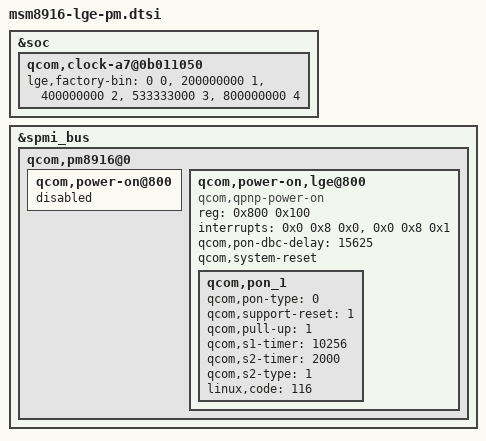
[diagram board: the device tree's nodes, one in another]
/* Copyright (c) 2012, Code Aurora Forum. All rights reserved.
 *
 * This program is free software; you can redistribute it and/or modify
 * it under the terms of the GNU General Public License version 2 and
 * only version 2 as published by the Free Software Foundation.
 *
 * This program is distributed in the hope that it will be useful,
 * but WITHOUT ANY WARRANTY; without even the implied warranty of
 * MERCHANTABILITY or FITNESS FOR A PARTICULAR PURPOSE.  See the
 * GNU General Public License for more details.
 */

&soc{
	qcom,clock-a7@0b011050	{
		lge,factory-bin =
			<          0 0>,
			<  200000000 1>,
			<  400000000 2>,
			<  533333000 3>,
			<  800000000 4>;
	};
};

&spmi_bus {
	qcom,pm8916@0 {
		qcom,power-on@800 {
			status = "disable";
		};
		qcom,power-on,lge@800 {
			compatible = "qcom,qpnp-power-on";
			reg = <0x800 0x100>;
			interrupts = <0x0 0x8 0x0>,
				     <0x0 0x8 0x1>;
			interrupt-names = "kpdpwr", "resin";
			qcom,pon-dbc-delay = <15625>;
			qcom,system-reset;

			qcom,pon_1 {
				qcom,pon-type = <0>;
				qcom,support-reset = <1>;
				qcom,pull-up = <1>;
				qcom,s1-timer = <10256>;
				qcom,s2-timer = <2000>;
				qcom,s2-type = <1>;
				linux,code = <116>;
			};
		};
	};
};
